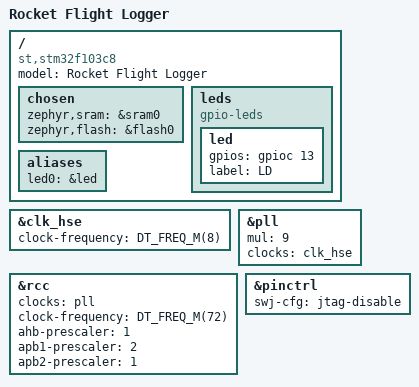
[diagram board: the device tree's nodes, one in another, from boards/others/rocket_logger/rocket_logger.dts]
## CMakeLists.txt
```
cmake_minimum_required(VERSION 3.20.0)

# list(APPEND BOARD_ROOT ${CMAKE_CURRENT_SOURCE_DIR})
# message(FATAL_ERROR ${BOARD_ROOT})

find_package(Zephyr REQUIRED HINTS $ENV{ZEPHYR_BASE})

project(flight_logger LANGUAGES C)


target_sources(app PRIVATE src/main.c)
```

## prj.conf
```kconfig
CONFIG_GPIO=y
CONFIG_PINCTRL=y
CONFIG_CLOCK_CONTROL=y
```

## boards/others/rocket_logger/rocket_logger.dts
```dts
/dts-v1/;
#include <st/f1/stm32f103X8.dtsi>
#include <st/f1/stm32f103r(8-b)tx-pinctrl.dtsi>

/ {
    model = "Rocket Flight Logger";
    compatible = "st,stm32f103c8";

    chosen {
        zephyr,sram = &sram0;
        zephyr,flash = &flash0;
    };

    leds {
        compatible = "gpio-leds";
        led: led {
            gpios = <&gpioc 13 GPIO_ACTIVE_HIGH>;
            label = "LD";
        };
    };

    aliases {
        led0 = &led;
    };
};

&clk_hse {
    clock-frequency = <DT_FREQ_M(8)>;
    status = "okay";
};

&pll {
    mul = <9>;
    clocks = <&clk_hse>;
    status = "okay";
};

&rcc {
	clocks = <&pll>;
	clock-frequency = <DT_FREQ_M(72)>;
	ahb-prescaler = <1>;
	apb1-prescaler = <2>;
	apb2-prescaler = <1>;
	/* usbpre not set: USB clock = 72 / 1.5: 48MHz */
};

&pinctrl {
    swj-cfg = "jtag-disable";
};
```

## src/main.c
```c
#include <stdio.h>
#include <zephyr/kernel.h>
#include <zephyr/drivers/gpio.h>

#define SLEEP_TIME_MS 1000

#define LED0_NODE DT_ALIAS(led0)

static const struct gpio_dt_spec led = GPIO_DT_SPEC_GET(LED0_NODE, gpios);

int main(void) {
    int ret;
    bool led_state = true;

    if (!gpio_is_ready_dt(&led)) {
        // return 0;
    }

    ret = gpio_pin_configure_dt(&led, GPIO_OUTPUT_ACTIVE);
    // if (ret < 0) {
    //     return 0;
    // }

    while(1) {
        ret = gpio_pin_toggle_dt(&led);
        if (ret < 0) {
            return 0;
        }

        led_state = !led_state;
        k_msleep(SLEEP_TIME_MS);
    }
}
```
